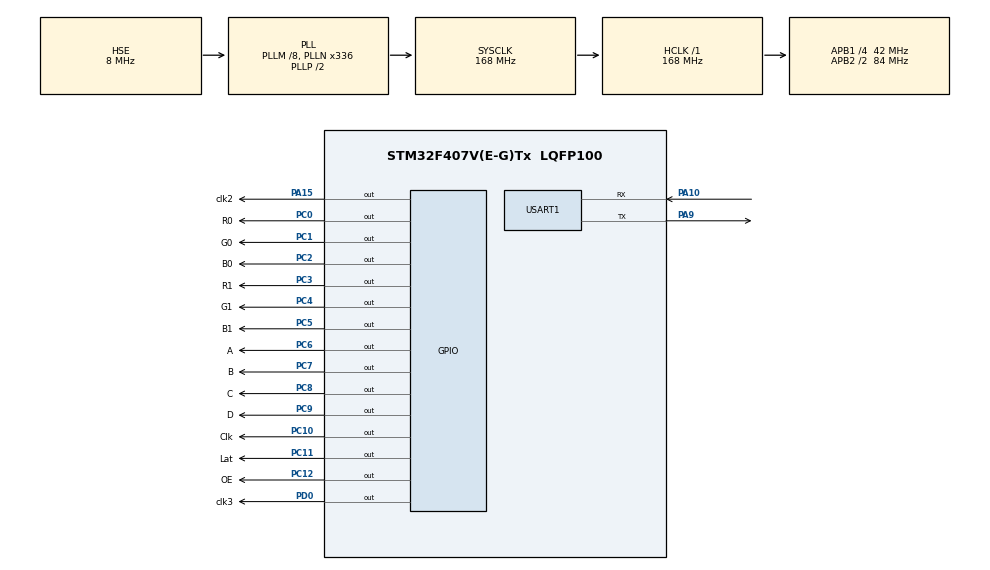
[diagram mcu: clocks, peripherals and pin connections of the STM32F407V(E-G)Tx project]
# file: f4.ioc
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Mcu.Family=STM32F4
Mcu.Name=STM32F407V(E-G)Tx
Mcu.Package=LQFP100
NVIC.PriorityGroup=NVIC_PRIORITYGROUP_0
NVIC.TIM1_UP_TIM10_IRQn=true\:0\:0\:false\:false\:true\:true\:true
NVIC.USART1_IRQn=true\:0\:0\:false\:false\:true\:true\:true
PA10.Mode=Asynchronous
PA10.Signal=USART1_RX
PA13.Mode=Trace_Asynchronous_SW
PA13.Signal=SYS_JTMS-SWDIO
PA14.Mode=Trace_Asynchronous_SW
PA14.Signal=SYS_JTCK-SWCLK
PA15.GPIO_Label=clk2
PA15.Signal=GPIO_Output
PA9.Mode=Asynchronous
PA9.Signal=USART1_TX
PB3.Mode=Trace_Asynchronous_SW
PB3.Signal=SYS_JTDO-SWO
PC0.GPIO_Label=R0
PC0.GPIO_ModeDefaultOutputPP=GPIO_MODE_OUTPUT_PP
PC0.GPIO_PuPd=GPIO_PULLUP
PC0.GPIO_Speed=GPIO_SPEED_FREQ_LOW
PC0.Signal=GPIO_Output
PC1.GPIO_Label=G0
PC1.GPIO_ModeDefaultOutputPP=GPIO_MODE_OUTPUT_PP
PC1.GPIO_PuPd=GPIO_PULLUP
PC1.GPIO_Speed=GPIO_SPEED_FREQ_LOW
PC1.Signal=GPIO_Output
PC10.GPIO_Label=Clk
PC10.GPIO_ModeDefaultOutputPP=GPIO_MODE_OUTPUT_PP
PC10.GPIO_PuPd=GPIO_PULLUP
PC10.GPIO_Speed=GPIO_SPEED_FREQ_LOW
PC10.Signal=GPIO_Output
PC11.GPIO_Label=Lat
PC11.GPIO_ModeDefaultOutputPP=GPIO_MODE_OUTPUT_PP
PC11.GPIO_PuPd=GPIO_PULLUP
PC11.GPIO_Speed=GPIO_SPEED_FREQ_VERY_HIGH
PC11.Signal=GPIO_Output
PC12.GPIO_Label=OE
PC12.GPIO_ModeDefaultOutputPP=GPIO_MODE_OUTPUT_PP
PC12.GPIO_PuPd=GPIO_PULLUP
PC12.GPIO_Speed=GPIO_SPEED_FREQ_VERY_HIGH
PC12.Signal=GPIO_Output
PC14-OSC32_IN.Mode=LSE-External-Oscillator
PC14-OSC32_IN.Signal=RCC_OSC32_IN
PC15-OSC32_OUT.Mode=LSE-External-Oscillator
PC15-OSC32_OUT.Signal=RCC_OSC32_OUT
PC2.GPIO_Label=B0
PC2.GPIO_ModeDefaultOutputPP=GPIO_MODE_OUTPUT_PP
PC2.GPIO_PuPd=GPIO_PULLUP
PC2.GPIO_Speed=GPIO_SPEED_FREQ_LOW
PC2.Signal=GPIO_Output
PC3.GPIO_Label=R1
PC3.GPIO_ModeDefaultOutputPP=GPIO_MODE_OUTPUT_PP
PC3.GPIO_PuPd=GPIO_PULLUP
PC3.GPIO_Speed=GPIO_SPEED_FREQ_LOW
PC3.Signal=GPIO_Output
PC4.GPIO_Label=G1
PC4.GPIO_ModeDefaultOutputPP=GPIO_MODE_OUTPUT_PP
PC4.GPIO_PuPd=GPIO_PULLUP
PC4.GPIO_Speed=GPIO_SPEED_FREQ_LOW
PC4.Signal=GPIO_Output
PC5.GPIO_Label=B1
PC5.GPIO_ModeDefaultOutputPP=GPIO_MODE_OUTPUT_PP
PC5.GPIO_PuPd=GPIO_PULLUP
PC5.GPIO_Speed=GPIO_SPEED_FREQ_LOW
PC5.Signal=GPIO_Output
PC6.GPIO_Label=A
PC6.GPIO_ModeDefaultOutputPP=GPIO_MODE_OUTPUT_PP
PC6.GPIO_PuPd=GPIO_NOPULL
PC6.GPIO_Speed=GPIO_SPEED_FREQ_LOW
PC6.Signal=GPIO_Output
PC7.GPIO_Label=B
PC7.GPIO_ModeDefaultOutputPP=GPIO_MODE_OUTPUT_PP
PC7.GPIO_PuPd=GPIO_NOPULL
PC7.GPIO_Speed=GPIO_SPEED_FREQ_LOW
PC7.Signal=GPIO_Output
PC8.GPIO_Label=C
PC8.GPIO_ModeDefaultOutputPP=GPIO_MODE_OUTPUT_PP
PC8.GPIO_PuPd=GPIO_NOPULL
PC8.GPIO_Speed=GPIO_SPEED_FREQ_LOW
PC8.Signal=GPIO_Output
PC9.GPIO_Label=D
PC9.GPIO_ModeDefaultOutputPP=GPIO_MODE_OUTPUT_PP
PC9.GPIO_PuPd=GPIO_PULLUP
PC9.GPIO_Speed=GPIO_SPEED_FREQ_LOW
PC9.Signal=GPIO_Output
PD0.GPIO_Label=clk3
PD0.Signal=GPIO_Output
PH0-OSC_IN.Mode=HSE-External-Oscillator
PH0-OSC_IN.Signal=RCC_OSC_IN
PH1-OSC_OUT.Mode=HSE-External-Oscillator
PH1-OSC_OUT.Signal=RCC_OSC_OUT
ProjectManager.HeapSize=0x200
ProjectManager.StackSize=0x400
ProjectManager.TargetToolchain=STM32CubeIDE
RCC.48MHZClocksFreq_Value=48000000
RCC.AHBFreq_Value=168000000
RCC.APB1CLKDivider=RCC_HCLK_DIV4
RCC.APB1Freq_Value=42000000
RCC.APB1TimFreq_Value=84000000
RCC.APB2CLKDivider=RCC_HCLK_DIV2
RCC.APB2Freq_Value=84000000
RCC.APB2TimFreq_Value=168000000
RCC.CortexFreq_Value=168000000
RCC.HCLKFreq_Value=168000000
RCC.HSE_VALUE=8000000
RCC.HSI_VALUE=16000000
RCC.PLLM=8
RCC.PLLN=336
RCC.PLLQ=7
RCC.PLLSourceVirtual=RCC_PLLSOURCE_HSE
RCC.SYSCLKFreq_VALUE=168000000
RCC.SYSCLKSource=RCC_SYSCLKSOURCE_PLLCLK
RCC.VCOOutputFreq_Value=336000000
TIM10.Period=2
TIM10.Prescaler=50
USART1.VirtualMode=VM_ASYNC
VP_TIM10_VS_ClockSourceINT.Mode=Enable_Timer
board=STM32F407G-DISC1

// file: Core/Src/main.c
/* USER CODE BEGIN Header */
/**
  ******************************************************************************
  * @file           : main.c
  * @brief          : Main program body
  ******************************************************************************
  * @attention
  *
  * <h2><center>&copy; Copyright (c) 2020 STMicroelectronics.
  * All rights reserved.</center></h2>
  *
  * This software component is licensed by ST under BSD 3-Clause license,
  * the "License"; You may not use this file except in compliance with the
  * License. You may obtain a copy of the License at:
  *                        opensource.org/licenses/BSD-3-Clause
  *
  ******************************************************************************
  */
/* USER CODE END Header */
#include "main.h"

TIM_HandleTypeDef htim10;

UART_HandleTypeDef huart1;

/* USER CODE BEGIN PV */
/* Private variables ---------------------------------------------------------*/

/* USER CODE END PV */

void SystemClock_Config(void);
static void MX_GPIO_Init(void);
static void MX_TIM10_Init(void);
static void MX_USART1_UART_Init(void);
/* USER CODE BEGIN PFP */
/* Private function prototypes -----------------------------------------------*/

/* USER CODE END PFP */

int main(void)
{

  /* MCU Configuration--------------------------------------------------------*/

  /* Reset of all peripherals, Initializes the Flash interface and the Systick. */
  HAL_Init();

  /* Configure the system clock */
  SystemClock_Config();

  /* Initialize all configured peripherals */
  MX_GPIO_Init();
  MX_TIM10_Init();
  MX_USART1_UART_Init();
  /* USER CODE BEGIN 2 */
  HAL_GPIO_WritePin(GPIOC, clk2_Pin, GPIO_PIN_RESET);
  HAL_GPIO_WritePin(GPIOC, Lat_Pin, GPIO_PIN_RESET);
  HAL_GPIO_WritePin(OE_GPIO_Port, OE_Pin, GPIO_PIN_RESET);
//  HAL_TIM_Base_Start_IT(&htim11);
  HAL_TIM_Base_Start_IT(&htim10);
  HAL_UART_Receive_IT(&huart1, data, 2);
  /* USER CODE END 2 */

  /* Infinite loop */
    while (1) {

    }
}

void SystemClock_Config(void)
{
  RCC_OscInitTypeDef RCC_OscInitStruct = {0};
  RCC_ClkInitTypeDef RCC_ClkInitStruct = {0};

  /** Configure the main internal regulator output voltage
  */
  __HAL_RCC_PWR_CLK_ENABLE();
  __HAL_PWR_VOLTAGESCALING_CONFIG(PWR_REGULATOR_VOLTAGE_SCALE1);
  /** Initializes the RCC Oscillators according to the specified parameters
  * in the RCC_OscInitTypeDef structure.
  */
  RCC_OscInitStruct.OscillatorType = RCC_OSCILLATORTYPE_HSE;
  RCC_OscInitStruct.HSEState = RCC_HSE_ON;
  RCC_OscInitStruct.PLL.PLLState = RCC_PLL_ON;
  RCC_OscInitStruct.PLL.PLLSource = RCC_PLLSOURCE_HSE;
  RCC_OscInitStruct.PLL.PLLM = 8;
  RCC_OscInitStruct.PLL.PLLN = 336;
  RCC_OscInitStruct.PLL.PLLP = RCC_PLLP_DIV2;
  RCC_OscInitStruct.PLL.PLLQ = 7;
  if (HAL_RCC_OscConfig(&RCC_OscInitStruct) != HAL_OK)
  {
    Error_Handler();
  }
  /** Initializes the CPU, AHB and APB buses clocks
  */
  RCC_ClkInitStruct.ClockType = RCC_CLOCKTYPE_HCLK|RCC_CLOCKTYPE_SYSCLK
                              |RCC_CLOCKTYPE_PCLK1|RCC_CLOCKTYPE_PCLK2;
  RCC_ClkInitStruct.SYSCLKSource = RCC_SYSCLKSOURCE_PLLCLK;
  RCC_ClkInitStruct.AHBCLKDivider = RCC_SYSCLK_DIV1;
  RCC_ClkInitStruct.APB1CLKDivider = RCC_HCLK_DIV4;
  RCC_ClkInitStruct.APB2CLKDivider = RCC_HCLK_DIV2;

  if (HAL_RCC_ClockConfig(&RCC_ClkInitStruct, FLASH_LATENCY_5) != HAL_OK)
  {
    Error_Handler();
  }
}

static void MX_TIM10_Init(void)
{

  htim10.Instance = TIM10;
  htim10.Init.Prescaler = 50;
  htim10.Init.CounterMode = TIM_COUNTERMODE_UP;
  htim10.Init.Period = 2;
  htim10.Init.ClockDivision = TIM_CLOCKDIVISION_DIV1;
  htim10.Init.AutoReloadPreload = TIM_AUTORELOAD_PRELOAD_DISABLE;
  if (HAL_TIM_Base_Init(&htim10) != HAL_OK)
  {
    Error_Handler();
  }

}

static void MX_USART1_UART_Init(void)
{

  huart1.Instance = USART1;
  huart1.Init.BaudRate = 115200;
  huart1.Init.WordLength = UART_WORDLENGTH_8B;
  huart1.Init.StopBits = UART_STOPBITS_1;
  huart1.Init.Parity = UART_PARITY_NONE;
  huart1.Init.Mode = UART_MODE_TX_RX;
  huart1.Init.HwFlowCtl = UART_HWCONTROL_NONE;
  huart1.Init.OverSampling = UART_OVERSAMPLING_16;
  if (HAL_UART_Init(&huart1) != HAL_OK)
  {
    Error_Handler();
  }

}

static void MX_GPIO_Init(void)
{
  GPIO_InitTypeDef GPIO_InitStruct = {0};

  /* GPIO Ports Clock Enable */
  __HAL_RCC_GPIOC_CLK_ENABLE();
  __HAL_RCC_GPIOH_CLK_ENABLE();
  __HAL_RCC_GPIOA_CLK_ENABLE();
  __HAL_RCC_GPIOD_CLK_ENABLE();
  __HAL_RCC_GPIOB_CLK_ENABLE();

  /*Configure GPIO pin Output Level */
  HAL_GPIO_WritePin(GPIOC, R0_Pin|G0_Pin|B0_Pin|R1_Pin
                          |G1_Pin|B1_Pin|A_Pin|B_Pin
                          |C_Pin|D_Pin|Clk_Pin|Lat_Pin
                          |OE_Pin, GPIO_PIN_RESET);

  /*Configure GPIO pin Output Level */
  HAL_GPIO_WritePin(clk2_GPIO_Port, clk2_Pin, GPIO_PIN_RESET);

  /*Configure GPIO pin Output Level */
  HAL_GPIO_WritePin(clk3_GPIO_Port, clk3_Pin, GPIO_PIN_RESET);

  /*Configure GPIO pins : R0_Pin G0_Pin B0_Pin R1_Pin
                           G1_Pin B1_Pin D_Pin Clk_Pin */
  GPIO_InitStruct.Pin = R0_Pin|G0_Pin|B0_Pin|R1_Pin
                          |G1_Pin|B1_Pin|D_Pin|Clk_Pin;
  GPIO_InitStruct.Mode = GPIO_MODE_OUTPUT_PP;
  GPIO_InitStruct.Pull = GPIO_PULLUP;
  GPIO_InitStruct.Speed = GPIO_SPEED_FREQ_LOW;
  HAL_GPIO_Init(GPIOC, &GPIO_InitStruct);

  /*Configure GPIO pins : A_Pin B_Pin C_Pin */
  GPIO_InitStruct.Pin = A_Pin|B_Pin|C_Pin;
  GPIO_InitStruct.Mode = GPIO_MODE_OUTPUT_PP;
  GPIO_InitStruct.Pull = GPIO_NOPULL;
  GPIO_InitStruct.Speed = GPIO_SPEED_FREQ_LOW;
  HAL_GPIO_Init(GPIOC, &GPIO_InitStruct);

  /*Configure GPIO pin : clk2_Pin */
  GPIO_InitStruct.Pin = clk2_Pin;
  GPIO_InitStruct.Mode = GPIO_MODE_OUTPUT_PP;
  GPIO_InitStruct.Pull = GPIO_NOPULL;
  GPIO_InitStruct.Speed = GPIO_SPEED_FREQ_LOW;
  HAL_GPIO_Init(clk2_GPIO_Port, &GPIO_InitStruct);

  /*Configure GPIO pins : Lat_Pin OE_Pin */
  GPIO_InitStruct.Pin = Lat_Pin|OE_Pin;
  GPIO_InitStruct.Mode = GPIO_MODE_OUTPUT_PP;
  GPIO_InitStruct.Pull = GPIO_PULLUP;
  GPIO_InitStruct.Speed = GPIO_SPEED_FREQ_VERY_HIGH;
  HAL_GPIO_Init(GPIOC, &GPIO_InitStruct);

  /*Configure GPIO pin : clk3_Pin */
  GPIO_InitStruct.Pin = clk3_Pin;
  GPIO_InitStruct.Mode = GPIO_MODE_OUTPUT_PP;
  GPIO_InitStruct.Pull = GPIO_NOPULL;
  GPIO_InitStruct.Speed = GPIO_SPEED_FREQ_LOW;
  HAL_GPIO_Init(clk3_GPIO_Port, &GPIO_InitStruct);

}

/* USER CODE BEGIN 4 */
void HAL_UART_RxCpltCallback(UART_HandleTypeDef *huart)
{
	slots_left = data[0];
	slots_occ = data[1];
	ChangeMatrix();
	HAL_UART_Receive_IT(huart, data, 2);
}
/* USER CODE END 4 */

void Error_Handler(void)
{
  /* USER CODE BEGIN Error_Handler_Debug */
    /* User can add his own implementation to report the HAL error return state
     */
    while (1) {}
  /* USER CODE END Error_Handler_Debug */
}

#ifdef  USE_FULL_ASSERT
/**
  * @brief  Reports the name of the source file and the source line number
  *         where the assert_param error has occurred.
  * @param  file: pointer to the source file name
  * @param  line: assert_param error line source number
  * @retval None
  */
void assert_failed(uint8_t *file, uint32_t line)
{
  /* USER CODE BEGIN 6 */
    /* User can add his own implementation to report the file name and line
       number, tex: printf("Wrong parameters value: file %s on line %d\r\n",
       file, line) */
  /* USER CODE END 6 */
}
#endif /* USE_FULL_ASSERT */

/************************ (C) COPYRIGHT STMicroelectronics *****END OF FILE****/
